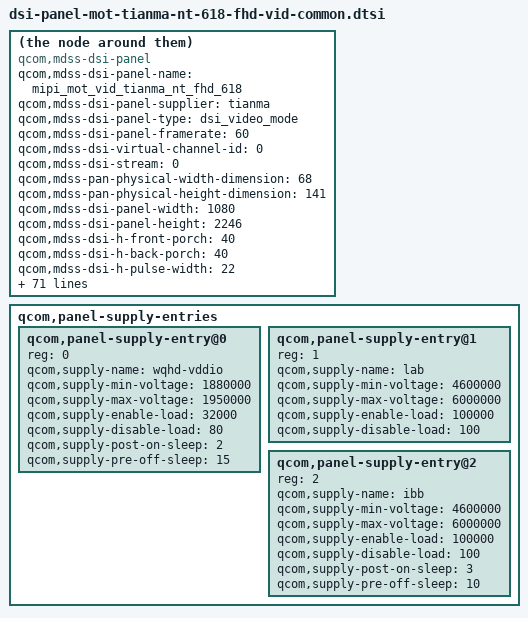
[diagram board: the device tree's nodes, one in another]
/* Copyright (c) 2018, The Linux Foundation. All rights reserved.
 *
 * This program is free software; you can redistribute it and/or modify
 * it under the terms of the GNU General Public License version 2 and
 * only version 2 as published by the Free Software Foundation.
 *
 * This program is distributed in the hope that it will be useful,
 * but WITHOUT ANY WARRANTY; without even the implied warranty of
 * MERCHANTABILITY or FITNESS FOR A PARTICULAR PURPOSE.  See the
 * GNU General Public License for more details.
 */

compatible = "qcom,mdss-dsi-panel";
qcom,mdss-dsi-panel-name = "mipi_mot_vid_tianma_nt_fhd_618";
qcom,mdss-dsi-panel-supplier = "tianma";
qcom,mdss-dsi-panel-type = "dsi_video_mode";
qcom,mdss-dsi-panel-framerate = <60>;
qcom,mdss-dsi-virtual-channel-id = <0>;
qcom,mdss-dsi-stream = <0>;
qcom,mdss-pan-physical-width-dimension = <68>;
qcom,mdss-pan-physical-height-dimension = <141>;

qcom,mdss-dsi-panel-width = <1080>;
qcom,mdss-dsi-panel-height = <2246>;
qcom,mdss-dsi-h-front-porch = <40>;
qcom,mdss-dsi-h-back-porch = <40>;
qcom,mdss-dsi-h-pulse-width = <22>;
qcom,mdss-dsi-v-front-porch = <10>;
qcom,mdss-dsi-v-back-porch = <8>;
qcom,mdss-dsi-v-pulse-width = <2>;
qcom,mdss-dsi-h-left-border = <0>;
qcom,mdss-dsi-h-right-border = <0>;
qcom,mdss-dsi-v-top-border = <0>;
qcom,mdss-dsi-v-bottom-border = <0>;
qcom,mdss-dsi-bpp = <24>;
qcom,mdss-dsi-underflow-color = <0xff>;
qcom,mdss-dsi-border-color = <0>;
qcom,mdss-dsi-on-command = [
	15 01 00 00 00 00 02 ff 20
	15 01 00 00 00 00 02 fb 01
	39 01 00 00 00 00 11 b0 00 00 00 36 00 70 00 99 00 b9 00 d4 00 eb 00 ff
	39 01 00 00 00 00 11 b1 01 10 01 4a 01 71 01 b0 01 da 02 21 02 54 02 56
	39 01 00 00 00 00 11 b2 02 89 02 c1 02 e7 03 17 03 35 03 5b 03 68 03 75
	39 01 00 00 00 00 0d b3 03 85 03 98 03 af 03 c9 03 d6 03 d8
	39 01 00 00 00 00 11 b4 00 00 00 3a 00 76 00 9f 00 bf 00 d9 00 f0 01 03
	39 01 00 00 00 00 11 b5 01 14 01 4d 01 73 01 b1 01 dc 02 21 02 54 02 56
	39 01 00 00 00 00 11 b6 02 8a 02 c1 02 e8 03 18 03 36 03 5c 03 6a 03 77
	39 01 00 00 00 00 0d b7 03 86 03 99 03 b1 03 ca 03 d6 03 d8
	39 01 00 00 00 00 11 b8 00 00 00 48 00 85 00 af 00 ce 00 e8 00 fd 01 10
	39 01 00 00 00 00 11 b9 01 20 01 57 01 7c 01 b8 01 e2 02 26 02 58 02 5a
	39 01 00 00 00 00 11 ba 02 8c 02 c4 02 ea 03 19 03 37 03 5d 03 6a 03 77
	39 01 00 00 00 00 0d bb 03 86 03 98 03 ae 03 c8 03 d6 03 d8
	15 01 00 00 00 00 02 ff 21
	15 01 00 00 00 00 02 fb 01
	39 01 00 00 00 00 11 b0 00 00 00 2e 00 68 00 91 00 b1 00 cc 00 e3 00 f7
	39 01 00 00 00 00 11 b1 01 08 01 42 01 69 01 a8 01 d2 02 19 02 4c 02 4e
	39 01 00 00 00 00 11 b2 02 81 02 b9 02 df 03 0f 03 2d 03 53 03 60 03 6d
	39 01 00 00 00 00 0d b3 03 7d 03 90 03 a7 03 c1 03 d6 03 d8
	39 01 00 00 00 00 11 b4 00 00 00 32 00 6e 00 97 00 b7 00 d1 00 e8 00 fb
	39 01 00 00 00 00 11 b5 01 0c 01 45 01 6b 01 a9 01 d4 02 19 02 4c 02 4e
	39 01 00 00 00 00 11 b6 02 82 02 b9 02 e0 03 10 03 2e 03 54 03 62 03 6f
	39 01 00 00 00 00 0d b7 03 7e 03 91 03 a9 03 c2 03 d6 03 d8
	39 01 00 00 00 00 11 b8 00 00 00 40 00 7d 00 a7 00 c6 00 e0 00 f5 01 08
	39 01 00 00 00 00 11 b9 01 18 01 4f 01 74 01 b0 01 da 02 1e 02 50 02 52
	39 01 00 00 00 00 11 ba 02 84 02 bc 02 e2 03 11 03 2f 03 55 03 62 03 6f
	39 01 00 00 00 00 0d bb 03 7e 03 90 03 a6 03 c0 03 d6 03 d8
	15 01 00 00 00 00 02 ff 10

	05 01 00 00 78 00 02 11 00
	05 01 00 00 0a 00 02 29 00
	//CABC PWM 20KHz
	15 01 00 00 00 00 02 FF 10
	15 01 00 00 00 00 02 FB 01
	15 01 00 00 00 00 02 51 CC
	15 01 00 00 00 00 02 53 2C
	15 01 00 00 00 00 02 55 01
	15 01 00 00 00 00 02 FF 23
	15 01 00 00 00 00 02 FB 01
	15 01 00 00 00 00 02 07 60
	15 01 00 00 00 00 02 08 01
	15 01 00 00 00 00 02 09 80
//ESD nice cmds from FAE
	15 01 00 00 00 00 02 FF 10
	15 01 00 00 00 00 02 B0 01
	15 01 00 00 00 00 02 FF 25
	15 01 00 00 00 00 02 FB 01
	15 01 00 00 00 00 02 18 B6
	15 01 00 00 00 00 02 19 0F
	15 01 00 00 00 00 02 FF F0
	15 01 00 00 00 00 02 CF 80
	15 01 00 00 00 00 02 FF D0
	15 01 00 00 00 00 02 FB 01
	15 01 00 00 00 00 02 24 21
	15 01 00 00 00 00 02 2A 10
	15 01 00 00 00 00 02 FF 10];/* display on */
qcom,mdss-dsi-off-command = [
	05 01 00 00 23 00 01 28		/* display_off */
	05 01 00 00 78 00 01 10];	/* enter sleep mode */


qcom,mdss-dsi-on-command-state = "dsi_lp_mode";
qcom,mdss-dsi-off-command-state = "dsi_lp_mode";

qcom,mdss-dsi-cabc-ui-command = [15 01 00 00 00 00 02 55 01];
qcom,mdss-dsi-cabc-ui-command-state = "dsi_hs_mode";
qcom,mdss-dsi-cabc-mv-command = [15 01 00 00 00 00 02 55 03];
qcom,mdss-dsi-cabc-mv-command-state = "dsi_hs_mode";
qcom,mdss-dsi-cabc-dis-command = [15 01 00 00 00 00 02 55 00];
qcom,mdss-dsi-cabc-dis-command-state = "dsi_hs_mode";
qcom,mdss-dsi-hbm-on-command = [15 01 00 00 00 00 02 51 FF];
qcom,mdss-dsi-hbm-on-command-state = "dsi_hs_mode";
qcom,mdss-dsi-hbm-off-command = [15 01 00 00 00 00 02 51 CC];
qcom,mdss-dsi-hbm-off-command-state = "dsi_hs_mode";
qcom,mdss-dsi-hbm-type = "lcd-dcs-wled";

qcom,mdss-dsi-h-sync-pulse = <0>;
qcom,mdss-dsi-traffic-mode = "burst_mode";
qcom,mdss-dsi-bllp-eof-power-mode;
qcom,mdss-dsi-bllp-power-mode;
qcom,mdss-dsi-lane-0-state;
qcom,mdss-dsi-lane-1-state;
qcom,mdss-dsi-lane-2-state;
qcom,mdss-dsi-lane-3-state;
qcom,mdss-dsi-panel-timings = [e6 38 26 00 68 6e 2a
		3c 44 03 04 00];
qcom,mdss-dsi-panel-timings-phy-v2 = [25 20 08 0a 06 03 04 a0
	25 20 08 0a 06 03 04 a0
	25 20 08 0a 06 03 04 a0
	25 20 08 0a 06 03 04 a0
	25 1d 08 0a 06 03 04 a0];
qcom,mdss-dsi-t-clk-post = <0x0e>;
qcom,mdss-dsi-t-clk-pre = <0x33>;
qcom,mdss-dsi-bl-min-level = <1>;
qcom,mdss-dsi-bl-max-level = <4095>;
qcom,mdss-dsi-dma-trigger = "trigger_sw";
qcom,mdss-dsi-mdp-trigger = "none";
qcom,mdss-dsi-bl-pmic-control-type = "bl_ctrl_wled";
qcom,mdss-dsi-reset-sequence = <1 2>, <0 2>, <1 10>;
qcom,mdss-dsi-lp11-init;
qcom,mdss-dsi-lp11-lcdb-reset;
qcom,mdss-dsi-tx-eot-append;
qcom,mdss-dsi-bl-shutdown-dcs;

qcom,esd-check-enabled;
qcom,mdss-dsi-panel-status-check-mode = "reg_read";
qcom,mdss-dsi-panel-status-read-length = <1>;
qcom,mdss-dsi-panel-status-command = [06 01 00 01 00 00 01 0A];
qcom,mdss-dsi-panel-status-command-state = "dsi_hs_mode";
qcom,mdss-dsi-panel-status-value = <0x9c>;

qcom,panel-supply-entries {
	#address-cells = <1>;
	#size-cells = <0>;

	qcom,panel-supply-entry@0 {
		reg = <0>;
		qcom,supply-name = "wqhd-vddio";
		qcom,supply-min-voltage = <1880000>;
		qcom,supply-max-voltage = <1950000>;
		qcom,supply-enable-load = <32000>;
		qcom,supply-disable-load = <80>;
		qcom,supply-post-on-sleep = <2>;
		qcom,supply-pre-off-sleep = <15>;
	};

	qcom,panel-supply-entry@1 {
		reg = <1>;
		qcom,supply-name = "lab";
		qcom,supply-min-voltage = <4600000>;
		qcom,supply-max-voltage = <6000000>;
		qcom,supply-enable-load = <100000>;
		qcom,supply-disable-load = <100>;
	};

	qcom,panel-supply-entry@2 {
		reg = <2>;
		qcom,supply-name = "ibb";
		qcom,supply-min-voltage = <4600000>;
		qcom,supply-max-voltage = <6000000>;
		qcom,supply-enable-load = <100000>;
		qcom,supply-disable-load = <100>;
		qcom,supply-post-on-sleep = <3>;
		qcom,supply-pre-off-sleep = <10>;
	};
};
